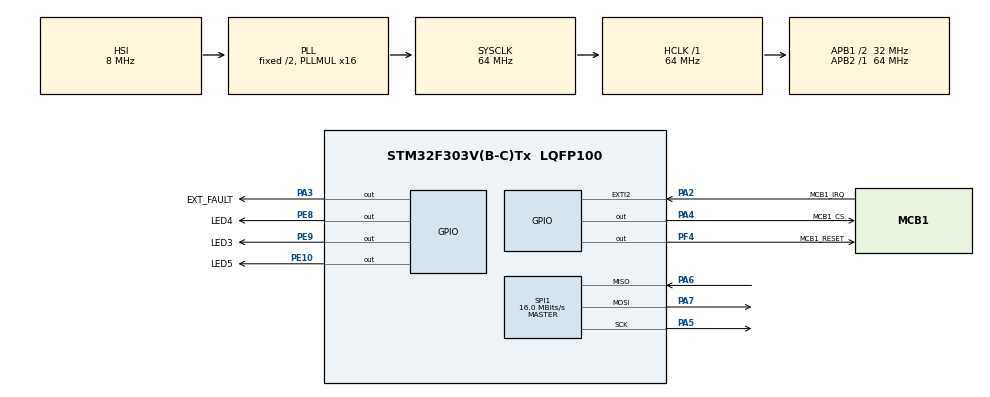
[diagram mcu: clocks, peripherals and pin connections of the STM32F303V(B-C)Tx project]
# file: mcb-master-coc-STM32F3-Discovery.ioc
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Mcu.Family=STM32F3
Mcu.Name=STM32F303V(B-C)Tx
Mcu.Package=LQFP100
NVIC.PriorityGroup=NVIC_PRIORITYGROUP_4
NVIC.TIM2_IRQn=true\:0\:0\:false\:false\:true\:true\:true
PA13.Mode=Serial_Wire
PA13.Signal=SYS_JTMS-SWDIO
PA14.Mode=Serial_Wire
PA14.Signal=SYS_JTCK-SWCLK
PA2.GPIO_Label=MCB1_IRQ
PA2.Signal=GPXTI2
PA3.GPIO_Label=EXT_FAULT
PA3.Signal=GPIO_Output
PA4.GPIO_Label=MCB1_CS
PA4.GPIO_Speed=GPIO_SPEED_FREQ_HIGH
PA4.Signal=GPIO_Output
PA5.Mode=Full_Duplex_Master
PA5.Signal=SPI1_SCK
PA6.Mode=Full_Duplex_Master
PA6.Signal=SPI1_MISO
PA7.Mode=Full_Duplex_Master
PA7.Signal=SPI1_MOSI
PE10.GPIO_Label=LED5
PE10.Signal=GPIO_Output
PE8.GPIO_Label=LED4
PE8.Signal=GPIO_Output
PE9.GPIO_Label=LED3
PE9.Signal=GPIO_Output
PF4.GPIO_Label=MCB1_RESET
PF4.Signal=GPIO_Output
ProjectManager.HeapSize=0x200
ProjectManager.StackSize=0x400
ProjectManager.TargetToolchain=STM32CubeIDE
RCC.AHBFreq_Value=64000000
RCC.APB1CLKDivider=RCC_HCLK_DIV2
RCC.APB1Freq_Value=32000000
RCC.APB1TimFreq_Value=64000000
RCC.APB2Freq_Value=64000000
RCC.APB2TimFreq_Value=64000000
RCC.CortexFreq_Value=64000000
RCC.HCLKFreq_Value=64000000
RCC.HSE_VALUE=8000000
RCC.HSI_VALUE=8000000
RCC.LSE_VALUE=32768
RCC.PLLMUL=RCC_PLL_MUL16
RCC.SYSCLKFreq_VALUE=64000000
RCC.SYSCLKSourceVirtual=RCC_SYSCLKSOURCE_PLLCLK
RCC.USBFreq_Value=64000000
SPI1.BaudRatePrescaler=SPI_BAUDRATEPRESCALER_4
SPI1.CLKPolarity=SPI_POLARITY_HIGH
SPI1.CRCCalculation=SPI_CRCCALCULATION_ENABLE
SPI1.CRCLength=SPI_CRC_LENGTH_16BIT
SPI1.CRCPolynomial=X12+X5+X0
SPI1.CalculateBaudRate=16.0 MBits/s
SPI1.DataSize=SPI_DATASIZE_16BIT
SPI1.Direction=SPI_DIRECTION_2LINES
SPI1.Mode=SPI_MODE_MASTER
SPI1.VirtualType=VM_MASTER
TIM2.Period=64000
VP_TIM2_VS_ClockSourceINT.Mode=Internal
board=custom

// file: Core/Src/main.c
/* USER CODE BEGIN Header */
/**
  ******************************************************************************
  * @file           : main.c
  * @brief          : Main program body
  ******************************************************************************
  * @attention
  *
  * <h2><center>&copy; Copyright (c) 2020 STMicroelectronics.
  * All rights reserved.</center></h2>
  *
  * This software component is licensed by ST under BSD 3-Clause license,
  * the "License"; You may not use this file except in compliance with the
  * License. You may obtain a copy of the License at:
  *                        opensource.org/licenses/BSD-3-Clause
  *
  ******************************************************************************
  */
/* USER CODE END Header */
#include "main.h"

/* USER CODE BEGIN Includes */
#include "application.h"
#include <string.h>
/* USER CODE END Includes */

SPI_HandleTypeDef hspi1;

TIM_HandleTypeDef htim2;

void SystemClock_Config(void);
static void MX_GPIO_Init(void);
static void MX_SPI1_Init(void);
static void MX_TIM2_Init(void);

int main(void)
{

  /* MCU Configuration--------------------------------------------------------*/

  /* Reset of all peripherals, Initializes the Flash interface and the Systick. */
  HAL_Init();

  /* Configure the system clock */
  SystemClock_Config();

  /* Initialize all configured peripherals */
  MX_GPIO_Init();
  MX_SPI1_Init();
  MX_TIM2_Init();
  /* USER CODE BEGIN 2 */

  AppInit();
  /* USER CODE END 2 */

  /* Infinite loop */
  /* USER CODE BEGIN WHILE */

  AppStart();

  /** Start the timer used for cyclic communication */
  HAL_TIM_Base_Start_IT(&htim2);
  while (1)
  {
    /* USER CODE END WHILE */

    /* USER CODE BEGIN 3 */
	    if (AppLoop() != (int32_t)0L)
	    {
	        break;
	    }

	    HAL_Delay(1);
  }
  /* USER CODE END 3 */
}

void SystemClock_Config(void)
{
  RCC_OscInitTypeDef RCC_OscInitStruct = {0};
  RCC_ClkInitTypeDef RCC_ClkInitStruct = {0};

  /** Initializes the RCC Oscillators according to the specified parameters
  * in the RCC_OscInitTypeDef structure.
  */
  RCC_OscInitStruct.OscillatorType = RCC_OSCILLATORTYPE_HSI;
  RCC_OscInitStruct.HSIState = RCC_HSI_ON;
  RCC_OscInitStruct.HSICalibrationValue = RCC_HSICALIBRATION_DEFAULT;
  RCC_OscInitStruct.PLL.PLLState = RCC_PLL_ON;
  RCC_OscInitStruct.PLL.PLLSource = RCC_PLLSOURCE_HSI;
  RCC_OscInitStruct.PLL.PLLMUL = RCC_PLL_MUL16;
  if (HAL_RCC_OscConfig(&RCC_OscInitStruct) != HAL_OK)
  {
    Error_Handler();
  }
  /** Initializes the CPU, AHB and APB buses clocks
  */
  RCC_ClkInitStruct.ClockType = RCC_CLOCKTYPE_HCLK|RCC_CLOCKTYPE_SYSCLK
                              |RCC_CLOCKTYPE_PCLK1|RCC_CLOCKTYPE_PCLK2;
  RCC_ClkInitStruct.SYSCLKSource = RCC_SYSCLKSOURCE_PLLCLK;
  RCC_ClkInitStruct.AHBCLKDivider = RCC_SYSCLK_DIV1;
  RCC_ClkInitStruct.APB1CLKDivider = RCC_HCLK_DIV2;
  RCC_ClkInitStruct.APB2CLKDivider = RCC_HCLK_DIV1;

  if (HAL_RCC_ClockConfig(&RCC_ClkInitStruct, FLASH_LATENCY_2) != HAL_OK)
  {
    Error_Handler();
  }
}

static void MX_SPI1_Init(void)
{

  /* SPI1 parameter configuration*/
  hspi1.Instance = SPI1;
  hspi1.Init.Mode = SPI_MODE_MASTER;
  hspi1.Init.Direction = SPI_DIRECTION_2LINES;
  hspi1.Init.DataSize = SPI_DATASIZE_16BIT;
  hspi1.Init.CLKPolarity = SPI_POLARITY_HIGH;
  hspi1.Init.CLKPhase = SPI_PHASE_1EDGE;
  hspi1.Init.NSS = SPI_NSS_SOFT;
  hspi1.Init.BaudRatePrescaler = SPI_BAUDRATEPRESCALER_4;
  hspi1.Init.FirstBit = SPI_FIRSTBIT_MSB;
  hspi1.Init.TIMode = SPI_TIMODE_DISABLE;
  hspi1.Init.CRCCalculation = SPI_CRCCALCULATION_ENABLE;
  hspi1.Init.CRCPolynomial = 4129;
  hspi1.Init.CRCLength = SPI_CRC_LENGTH_16BIT;
  hspi1.Init.NSSPMode = SPI_NSS_PULSE_ENABLE;
  if (HAL_SPI_Init(&hspi1) != HAL_OK)
  {
    Error_Handler();
  }

}

static void MX_TIM2_Init(void)
{

  TIM_ClockConfigTypeDef sClockSourceConfig = {0};
  TIM_MasterConfigTypeDef sMasterConfig = {0};

  htim2.Instance = TIM2;
  htim2.Init.Prescaler = 0;
  htim2.Init.CounterMode = TIM_COUNTERMODE_UP;
  htim2.Init.Period = 64000;
  htim2.Init.ClockDivision = TIM_CLOCKDIVISION_DIV1;
  htim2.Init.AutoReloadPreload = TIM_AUTORELOAD_PRELOAD_DISABLE;
  if (HAL_TIM_Base_Init(&htim2) != HAL_OK)
  {
    Error_Handler();
  }
  sClockSourceConfig.ClockSource = TIM_CLOCKSOURCE_INTERNAL;
  if (HAL_TIM_ConfigClockSource(&htim2, &sClockSourceConfig) != HAL_OK)
  {
    Error_Handler();
  }
  sMasterConfig.MasterOutputTrigger = TIM_TRGO_RESET;
  sMasterConfig.MasterSlaveMode = TIM_MASTERSLAVEMODE_DISABLE;
  if (HAL_TIMEx_MasterConfigSynchronization(&htim2, &sMasterConfig) != HAL_OK)
  {
    Error_Handler();
  }

}

static void MX_GPIO_Init(void)
{
  GPIO_InitTypeDef GPIO_InitStruct = {0};

  /* GPIO Ports Clock Enable */
  __HAL_RCC_GPIOA_CLK_ENABLE();
  __HAL_RCC_GPIOF_CLK_ENABLE();
  __HAL_RCC_GPIOE_CLK_ENABLE();

  /*Configure GPIO pin Output Level */
  HAL_GPIO_WritePin(GPIOA, EXT_FAULT_Pin|MCB1_CS_Pin, GPIO_PIN_RESET);

  /*Configure GPIO pin Output Level */
  HAL_GPIO_WritePin(MCB1_RESET_GPIO_Port, MCB1_RESET_Pin, GPIO_PIN_RESET);

  /*Configure GPIO pin Output Level */
  HAL_GPIO_WritePin(GPIOE, LED4_Pin|LED3_Pin|LED5_Pin, GPIO_PIN_RESET);

  /*Configure GPIO pin : MCB1_IRQ_Pin */
  GPIO_InitStruct.Pin = MCB1_IRQ_Pin;
  GPIO_InitStruct.Mode = GPIO_MODE_IT_RISING;
  GPIO_InitStruct.Pull = GPIO_NOPULL;
  HAL_GPIO_Init(MCB1_IRQ_GPIO_Port, &GPIO_InitStruct);

  /*Configure GPIO pin : EXT_FAULT_Pin */
  GPIO_InitStruct.Pin = EXT_FAULT_Pin;
  GPIO_InitStruct.Mode = GPIO_MODE_OUTPUT_PP;
  GPIO_InitStruct.Pull = GPIO_NOPULL;
  GPIO_InitStruct.Speed = GPIO_SPEED_FREQ_LOW;
  HAL_GPIO_Init(EXT_FAULT_GPIO_Port, &GPIO_InitStruct);

  /*Configure GPIO pin : MCB1_RESET_Pin */
  GPIO_InitStruct.Pin = MCB1_RESET_Pin;
  GPIO_InitStruct.Mode = GPIO_MODE_OUTPUT_PP;
  GPIO_InitStruct.Pull = GPIO_NOPULL;
  GPIO_InitStruct.Speed = GPIO_SPEED_FREQ_LOW;
  HAL_GPIO_Init(MCB1_RESET_GPIO_Port, &GPIO_InitStruct);

  /*Configure GPIO pin : MCB1_CS_Pin */
  GPIO_InitStruct.Pin = MCB1_CS_Pin;
  GPIO_InitStruct.Mode = GPIO_MODE_OUTPUT_PP;
  GPIO_InitStruct.Pull = GPIO_NOPULL;
  GPIO_InitStruct.Speed = GPIO_SPEED_FREQ_HIGH;
  HAL_GPIO_Init(MCB1_CS_GPIO_Port, &GPIO_InitStruct);

  /*Configure GPIO pins : LED4_Pin LED3_Pin LED5_Pin */
  GPIO_InitStruct.Pin = LED4_Pin|LED3_Pin|LED5_Pin;
  GPIO_InitStruct.Mode = GPIO_MODE_OUTPUT_PP;
  GPIO_InitStruct.Pull = GPIO_NOPULL;
  GPIO_InitStruct.Speed = GPIO_SPEED_FREQ_LOW;
  HAL_GPIO_Init(GPIOE, &GPIO_InitStruct);

}

void Error_Handler(void)
{
}

/************************ (C) COPYRIGHT STMicroelectronics *****END OF FILE****/
